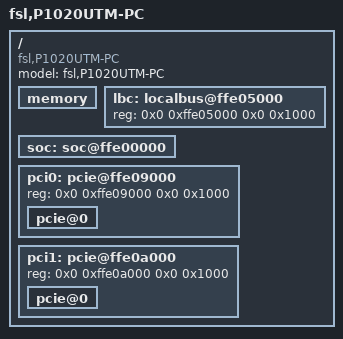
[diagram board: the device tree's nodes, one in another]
/include/ "p1020si-pre.dtsi"
/ {
	model = "fsl,P1020UTM-PC";
	compatible = "fsl,P1020UTM-PC";
	memory {
		device_type = "memory";
	};
	lbc: localbus@ffe05000 {
		reg = <0x0 0xffe05000 0x0 0x1000>;
		ranges = <0x0 0x0 0x0 0xec000000 0x02000000
			  0x1 0x0 0x0 0xffa00000 0x00040000
			  0x2 0x0 0x0 0xffb00000 0x00020000>;
	};
	soc: soc@ffe00000 {
		ranges = <0x0 0x0 0xffe00000 0x100000>;
	};
	pci0: pcie@ffe09000 {
		reg = <0x0 0xffe09000 0x0 0x1000>;
		ranges = <0x2000000 0x0 0xe0000000 0x0 0xa0000000 0x0 0x20000000
			  0x1000000 0x0 0x00000000 0x0 0xffc10000 0x0 0x10000>;
		pcie@0 {
			ranges = <0x2000000 0x0 0xe0000000
				  0x2000000 0x0 0xe0000000
				  0x0 0x20000000
				  0x1000000 0x0 0x0
				  0x1000000 0x0 0x0
				  0x0 0x100000>;
		};
	};
	pci1: pcie@ffe0a000 {
		reg = <0x0 0xffe0a000 0x0 0x1000>;
		ranges = <0x2000000 0x0 0xe0000000 0x0 0x80000000 0x0 0x20000000
			  0x1000000 0x0 0x00000000 0x0 0xffc00000 0x0 0x10000>;
		pcie@0 {
			ranges = <0x2000000 0x0 0xe0000000
				  0x2000000 0x0 0xe0000000
				  0x0 0x20000000
				  0x1000000 0x0 0x0
				  0x1000000 0x0 0x0
				  0x0 0x100000>;
		};
	};
};
/include/ "p1020utm-pc.dtsi"
/include/ "p1020si-post.dtsi"
